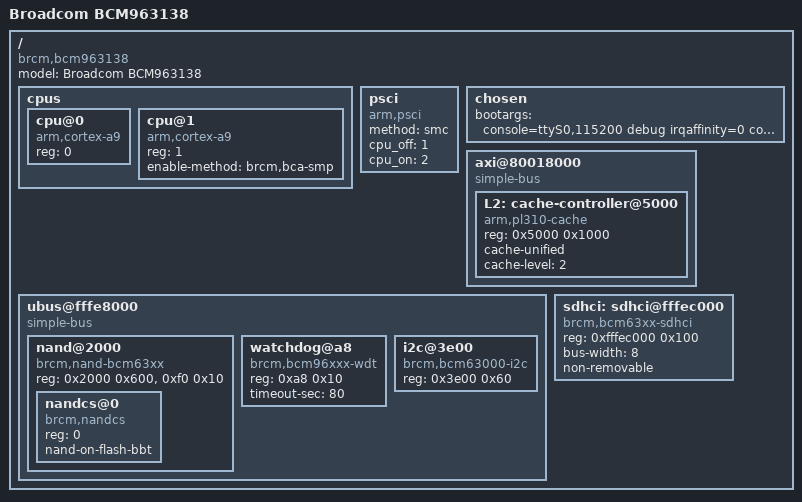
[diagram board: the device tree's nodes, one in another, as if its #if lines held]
/*
 * Broadcom BCM63138 Reference Board DTS
 */

/dts-v1/;
/memreserve/ 0x00001000 0x00007000;

#include "bcm_963xx_template.dtsi"

/ {
	compatible = "brcm,bcm963138";
	model = "Broadcom BCM963138";

	cpus {
		#address-cells = <1>;
		#size-cells = <0>;

		cpu@0 {
			device_type = "cpu";
			compatible = "arm,cortex-a9";
			reg = <0>;
		};

		cpu@1 {
			device_type = "cpu";
			compatible = "arm,cortex-a9";
			reg = <1>;
			enable-method = "brcm,bca-smp";
		};
	};

#if defined (CONFIG_BCM_ASTRA)
	psci {
		compatible	= "arm,psci";
		method		= "smc";
		cpu_off		= <1>;
		cpu_on		= <2>;
	};
#endif

	/* increase coherent_pool size for ARM-based chip */
	chosen {
		bootargs = "console=ttyS0,115200 debug irqaffinity=0 coherent_pool=1M cpuidle_sysfs_switch pci=pcie_bus_safe";
	};

	/* ARM bus */
	axi@80018000 {
		compatible = "simple-bus";
		ranges = <0 0x80018000 0x20000>;
		#address-cells = <1>;
		#size-cells = <1>;

		L2: cache-controller@5000 {
			compatible = "arm,pl310-cache";
			reg = <0x5000 0x1000>;
			cache-unified;
			cache-level = <2>;
		};
	};

	/* Legacy UBUS base */
	ubus@fffe8000 {
		compatible = "simple-bus";
		#address-cells = <1>;
		#size-cells = <1>;
		ranges = <0 0xfffe8000 0x8000>;

		nand@2000 {
			#address-cells = <1>;
			#size-cells = <0>;
			compatible = "brcm,nand-bcm63xx", "brcm,brcmnand-v7.0";
			reg = <0x2000 0x600>, <0xf0 0x10>;
			reg-names = "nand", "nand-int-base";
			status = "okay";

			nandcs@0 {
				compatible = "brcm,nandcs";
				reg = <0>;
				nand-on-flash-bbt;
			};

		};

		watchdog@a8 {
			compatible = "brcm,bcm96xxx-wdt";
			reg = <0xa8 0x10>;
			timeout-sec = <80>;
		};

		i2c@3e00 {
			compatible = "brcm,bcm63000-i2c";
			reg = <0x3e00 0x60>;
		};
	};

	sdhci: sdhci@fffec000 {
		compatible = "brcm,bcm63xx-sdhci";
		#address-cells = <1>;
		#size-cells = <1>;
		reg = <0xfffec000 0x100>;
		bus-width = <8>;
		non-removable;
	};
};
